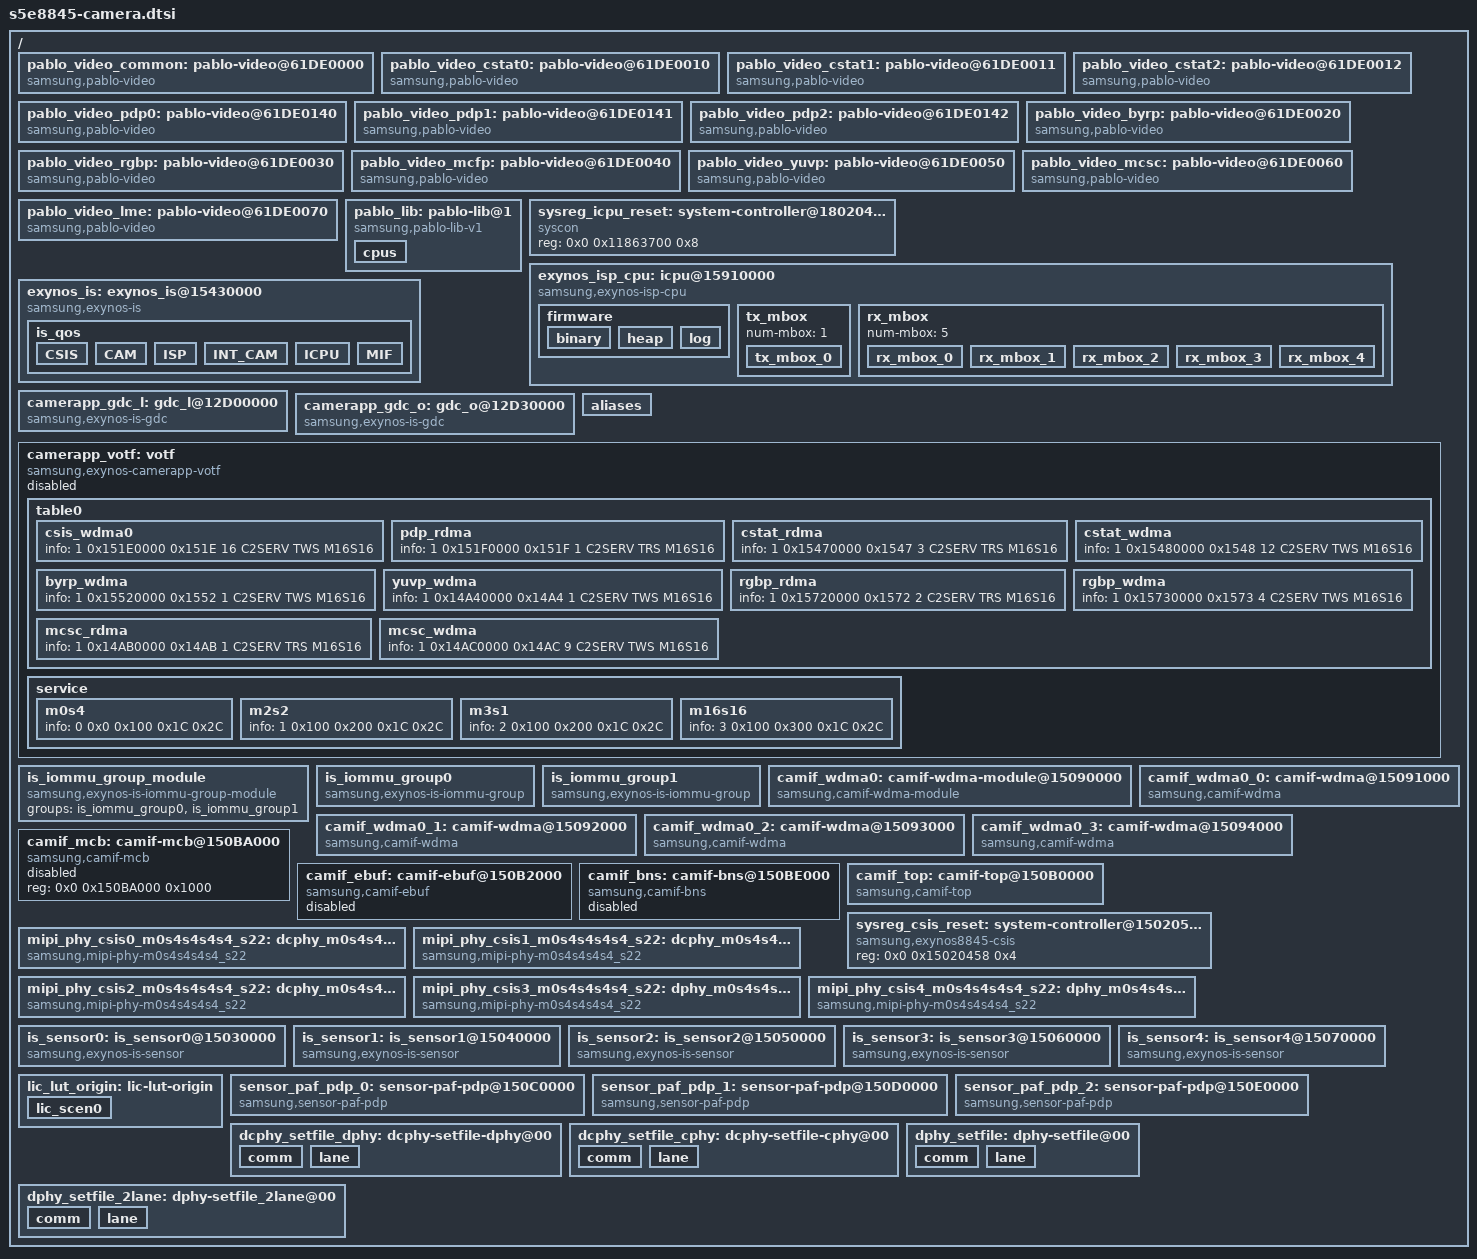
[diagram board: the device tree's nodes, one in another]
/*
 * SAMSUNG EXYNOS8845 SoC camera device tree source
 *
 * Copyright (c) 2023 Samsung Electronics Co., Ltd.
 *		http://www.samsung.com
 *
 * SAMSUNG EXYNOS8845 SoC camera device nodes are listed in this file.
 * EXYNOS8845 based board files can include this file and provide
 * values for board specfic bindings.
 *
 * This program is free software; you can redistribute it and/or modify
 * it under the terms of the GNU General Public License version 2 as
 * published by the Free Software Foundation.
 */

#include <dt-bindings/clock/s5e8845.h>
#include <dt-bindings/interrupt-controller/arm-gic.h>
#include <dt-bindings/interrupt-controller/s5e8845.h>
#include <dt-bindings/camera/exynos_is_dt.h>
#include <dt-bindings/camera/votf.h>
#include "s5e8845-pinctrl.dtsi"

/ {
	pablo_video_common: pablo-video@61DE0000 {
		compatible = "samsung,pablo-video";
		device-type = <1>;	/* ISCHAIN */
		video-type = <0>;	/* LEADER */
		video-name = "COMMON";
		video-number = <0>;
		group-id = <24>;
		group-slot = <0>;

		pablo,v4l2-dev = <&exynos_is>;
	};

	pablo_video_cstat0: pablo-video@61DE0010 {
		compatible = "samsung,pablo-video";
		device-type = <1>;      /* ISCHAIN */
		video-type = <0>;       /* LEADER */
		video-name = "CSTAT0";
		video-number = <10>;
		group-id = <0>;
		group-slot = <2>;

		pablo,v4l2-dev = <&exynos_is>;
	};

	pablo_video_cstat1: pablo-video@61DE0011 {
		compatible = "samsung,pablo-video";
		device-type = <1>;      /* ISCHAIN */
		video-type = <0>;       /* LEADER */
		video-name = "CSTAT1";
		video-number = <11>;
		group-id = <1>;
		group-slot = <2>;

		pablo,v4l2-dev = <&exynos_is>;
	};

	pablo_video_cstat2: pablo-video@61DE0012 {
		compatible = "samsung,pablo-video";
		device-type = <1>;      /* ISCHAIN */
		video-type = <0>;       /* LEADER */
		video-name = "CSTAT2";
		video-number = <12>;
		group-id = <2>;
		group-slot = <2>;

		pablo,v4l2-dev = <&exynos_is>;
	};

	pablo_video_pdp0: pablo-video@61DE0140 {
		compatible = "samsung,pablo-video";
		device-type = <1>;      /* ISCHAIN */
		video-type = <0>;       /* LEADER */
		video-name = "PDP0";
		video-number = <140>;
		group-id = <7>;
		group-slot = <1>;

		pablo,v4l2-dev = <&exynos_is>;
	};

	pablo_video_pdp1: pablo-video@61DE0141 {
		compatible = "samsung,pablo-video";
		device-type = <1>;      /* ISCHAIN */
		video-type = <0>;       /* LEADER */
		video-name = "PDP1";
		video-number = <141>;
		group-id = <8>;
		group-slot = <1>;

		pablo,v4l2-dev = <&exynos_is>;
	};

	pablo_video_pdp2: pablo-video@61DE0142 {
		compatible = "samsung,pablo-video";
		device-type = <1>;      /* ISCHAIN */
		video-type = <0>;       /* LEADER */
		video-name = "PDP2";
		video-number = <142>;
		group-id = <9>;
		group-slot = <1>;

		pablo,v4l2-dev = <&exynos_is>;
	};

	pablo_video_byrp: pablo-video@61DE0020 {
		compatible = "samsung,pablo-video";
		device-type = <1>;      /* ISCHAIN */
		video-type = <0>;       /* LEADER */
		video-name = "BYRP";
		video-number = <20>;
		group-id = <4>;
		group-slot = <4>;

		pablo,v4l2-dev = <&exynos_is>;
	};

	pablo_video_rgbp: pablo-video@61DE0030 {
		compatible = "samsung,pablo-video";
		device-type = <1>;      /* ISCHAIN */
		video-type = <0>;       /* LEADER */
		video-name = "RGBP";
		video-number = <30>;
		group-id = <5>;
		group-slot = <5>;

		pablo,v4l2-dev = <&exynos_is>;
	};

	pablo_video_mcfp: pablo-video@61DE0040 {
		compatible = "samsung,pablo-video";
		device-type = <1>;      /* ISCHAIN */
		video-type = <0>;       /* LEADER */
		video-name = "MCFP";
		video-number = <40>;
		group-id = <11>;
		group-slot = <6>;

		pablo,v4l2-dev = <&exynos_is>;
	};

	pablo_video_yuvp: pablo-video@61DE0050 {
		compatible = "samsung,pablo-video";
		device-type = <1>;      /* ISCHAIN */
		video-type = <0>;       /* LEADER */
		video-name = "YUVP";
		video-number = <50>;
		group-id = <12>;
		group-slot = <7>;

		pablo,v4l2-dev = <&exynos_is>;
	};

	pablo_video_mcsc: pablo-video@61DE0060 {
		compatible = "samsung,pablo-video";
		device-type = <1>;      /* ISCHAIN */
		video-type = <0>;       /* LEADER */
		video-name = "MCSC";
		video-number = <60>;
		group-id = <6>;
		group-slot = <8>;

		pablo,v4l2-dev = <&exynos_is>;
	};

	pablo_video_lme: pablo-video@61DE0070 {
		compatible = "samsung,pablo-video";
		device-type = <1>;      /* ISCHAIN */
		video-type = <0>;       /* LEADER */
		video-name = "LME";
		video-number = <70>;
		group-id = <13>;
		group-slot = <3>;

		pablo,v4l2-dev = <&exynos_is>;
	};

	pablo_lib: pablo-lib@1 {
		compatible = "samsung,pablo-lib-v1";
		status = "okay";

		cpus { /* 4:3:1 */
			cluster0 = <0>; /* LIT */
			cluster1 = <4>; /* MID */
			cluster2 = <7>; /* BIG */
		};
	};

	sysreg_icpu_reset: system-controller@1802040c {
		compatible = "syscon";
		reg = <0x0 0x11863700 0x8>;
	};

	exynos_isp_cpu: icpu@15910000 {
		compatible = "samsung,exynos-isp-cpu";
		reg = <0x0 0x15900000 0x50>,
			<0x0 0x15910000 0x1000>,
			<0x0 0x15970000 0x2000>,
			<0x0 0x15980000 0x100>;
		reg-names = "mcuctl_core", "mcuctl", "sysctrl", "cstore";
		interrupts = <0 INTREQ__FROM_ICPU_TO_HOST_3 IRQ_TYPE_LEVEL_HIGH>, /* mbox0 */
				<0 INTREQ__FROM_ICPU_TO_HOST_4 IRQ_TYPE_LEVEL_HIGH>, /* mbox1 */
				<0 INTREQ__FROM_ICPU_TO_HOST_5 IRQ_TYPE_LEVEL_HIGH>, /* mbox2 */
				<0 INTREQ__FROM_ICPU_TO_HOST_6 IRQ_TYPE_LEVEL_HIGH>, /* mbox3 */
				<0 INTREQ__FROM_ICPU_TO_HOST_7 IRQ_TYPE_LEVEL_HIGH>; /* mbox4 */
		clocks = <&clock GATE_ICPU_QCH_CPU0>;
		clock-names = "GATE_ICPU_QCH_CPU0";
		status = "okay";
		iommus = <&sysmmu_icpu_s0>;
		samsung,iommu-group = <&iommu_group_icpu>;
		samsung,reset-sysreg = <&sysreg_icpu_reset>;
		reset = <0>; /* reset bit */
		#dma-address-cells = <1>;
		#dma-size-cells = <1>;
		samsung,iommu-reserved-map =
			<0x0 0x10000000 0x1000000>, /* FW binary */
			<0x0 0x00000000 0x10000000>, /* ICPU MMU */
			<0x0 0x15900000 0x200000>; /* ICPU SFR */
		memory-region = <&icpu_fw_rmem>;

		force-powerdown-seq =
			/* type addr mask val timeout */
			<0 0x15970024 0xFFFFFFFF 0x1      0>, /* Enable CA32 Transaction block */
			<0 0x15980030 0xFFFFFFFF 0x3      0>, /* DMA Flush */
			<1 0x15970028 0xFFFFFFFF 0x0   1000>, /* Wait until # of CA32  transaction is 0 */
			<1 0x15980034 0x24       0x24  1000>, /* Wait DMA  flush is done */

			<0 0x15970004 0xFFFFFFFF 0x3F     0>, /* Q-channel disable(Always-on) */
			<0 0x15970030 0xFFFFFFFF 0x0      0>, /* Reset : Timers, WDT, GIC400, SYSCTRL */
			<0 0x1597002C 0xFFFFFFFF 0x0      0>, /* Reset : CA53, C_STORE */

			/* Need to PMU core reset */

			<0 0x15970004 0xFFFFFFFF 0x0      0>, /* Q-channel enable */
			<0 0x15803004 0xFFFFFFFF 0x4      0>, /* Q-ch & Clock Disable for ICPU_QCH_CPU0 */
			<0 0x1580300C 0xFFFFFFFF 0x4      0>, /* Q-ch & Clock Disable for ICPU_QCH_L2 */
			<0 0x15803010 0xFFFFFFFF 0x4      0>; /* Q-ch & Clock Disable for ICPU_QCH_NEON */

		samsung,imgloader-s2mpu-support;
		aarch64;
		firmware{
			binary{
				mem-id = <0>;
				cma-alloc;
				size = <0x1000000>;
				align = <0x200000>; /* 64K for S2MPU & ICPU MMU 2M page */
				signature-size = <0x210>; /* dec. 528 byte */
				signature-check;
				no-optimization;
			};

			heap{
				mem-id = <1>;
				dma-heap;
				heap-name = "system-uncached";
				size = <0x9600000>;
			};

			log{
				mem-id = <2>;
				dma-heap;
				heap-name = "system-uncached";
				size = <0x100000>;
			};
		};

		tx_mbox{
			num-mbox = <1>;
			tx_mbox_0{
				int-enable-offset = <0x1004>;
				int-gen-offset = <0x1400>;
				int-status-offset = <0x100c>;
				max-data-len = <16>;
				data-offset = <0x1440>;
			};
		};

		rx_mbox{
			num-mbox = <5>;
			rx_mbox_0{
				int-gen-offset = <0x1200>;
				int-status-offset = <0x1008>;
				max-data-len = <8>;
				data-offset = <0x1240>;
			};
			rx_mbox_1{
				int-gen-offset = <0x1204>;
				int-status-offset = <0x1008>;
				max-data-len = <8>;
				data-offset = <0x1260>;
			};
			rx_mbox_2{
				int-gen-offset = <0x1208>;
				int-status-offset = <0x1008>;
				max-data-len = <8>;
				data-offset = <0x1280>;
			};
			rx_mbox_3{
				int-gen-offset = <0x120c>;
				int-status-offset = <0x1008>;
				max-data-len = <8>;
				data-offset = <0x12a0>;
			};
			rx_mbox_4{
				int-gen-offset = <0x1210>;
				int-status-offset = <0x1008>;
				max-data-len = <8>;
				data-offset = <0x12c0>;
			};
		};
	};

	exynos_is: exynos_is@15430000 {
		compatible = "samsung,exynos-is";
		reg = <0x0 0x15430000 0x10000>, /* CSTAT0 */
			<0x0 0x15440000 0x10000>, /* CSTAT1 */
			<0x0 0x15450000 0x10000>, /* CSTAT2 */
			<0x0 0x12C80000 0x10000>, /* LME */
			<0x0 0x15500000 0x10000>, /* BYRP */
			<0x0 0x15700000 0x10000>, /* RGBP */
			<0x0 0x15780000 0x10000>, /* MCFP */
			<0x0 0x14A30000 0x10000>, /* YUVP */
			<0x0 0x14AA0000 0x10000>; /* MCSC */
		interrupts = <0 INTREQ__CSTAT_CH0_0 IRQ_TYPE_LEVEL_HIGH>, /*CSTAT0_0 */
			<0 INTREQ__CSTAT_CH0_1 IRQ_TYPE_LEVEL_HIGH>,      /* CSTAT0_1 */
			<0 INTREQ__CSTAT_CH1_0 IRQ_TYPE_LEVEL_HIGH>,      /* CSTAT1_0 */
			<0 INTREQ__CSTAT_CH1_1 IRQ_TYPE_LEVEL_HIGH>,      /* CSTAT1_1 */
			<0 INTREQ__CSTAT_CH2_0 IRQ_TYPE_LEVEL_HIGH>,      /* CSTAT2_0 */
			<0 INTREQ__CSTAT_CH2_1 IRQ_TYPE_LEVEL_HIGH>,      /* CSTAT2_1 */
			<0 INTREQ__LME_O_INT_0 IRQ_TYPE_LEVEL_HIGH>,       /* LME_0 */
			<0 INTREQ__BYRP_0 IRQ_TYPE_LEVEL_HIGH>,           /* BYRP_0 */
			<0 INTREQ__BYRP_1 IRQ_TYPE_LEVEL_HIGH>,           /* BYRP_1 */
			<0 INTREQ__RGBP_0 IRQ_TYPE_LEVEL_HIGH>,           /* RGBP_0 */
			<0 INTREQ__RGBP_1 IRQ_TYPE_LEVEL_HIGH>,           /* RGBP_1 */
			<0 INTREQ__MCFP_0 IRQ_TYPE_LEVEL_HIGH>,	/* MCFP_0 */
			<0 INTREQ__MCFP_1 IRQ_TYPE_LEVEL_HIGH>,	/* MCFP_1 */
			<0 INTREQ__YUVP_0 IRQ_TYPE_LEVEL_HIGH>,           /* YUVP_0 */
			<0 INTREQ__YUVP_1 IRQ_TYPE_LEVEL_HIGH>,           /* YUVP_1 */
			<0 INTREQ__MCSC_0 IRQ_TYPE_LEVEL_HIGH>,    /* MCSC_0 */
			<0 INTREQ__MCSC_1 IRQ_TYPE_LEVEL_HIGH>;    /* MCSC_1 */
		pinctrl-names = "default","release";
		pinctrl-0 = <>;
		pinctrl-1 = <>;
		clocks = <&clock GATE_DFTMUX_CMU_QCH_CIS_CLK0>,
		      <&clock GATE_DFTMUX_CMU_QCH_CIS_CLK1>,
		      <&clock GATE_DFTMUX_CMU_QCH_CIS_CLK2>,
		      <&clock GATE_DFTMUX_CMU_QCH_CIS_CLK3>,
		      <&clock GATE_DFTMUX_CMU_QCH_CIS_CLK4>,

		      <&clock DOUT_DIV_CLKCMU_CIS_CLK0>,
		      <&clock DOUT_DIV_CLKCMU_CIS_CLK1>,
		      <&clock DOUT_DIV_CLKCMU_CIS_CLK2>,
		      <&clock DOUT_DIV_CLKCMU_CIS_CLK3>,
		      <&clock DOUT_DIV_CLKCMU_CIS_CLK4>,

		      <&clock GATE_CSIS_PDP_QCH_DMA>,

		      <&clock GATE_MIPI_PHY_LINK_WRAP_QCH_CSIS0>,
		      <&clock GATE_MIPI_PHY_LINK_WRAP_QCH_CSIS1>,
		      <&clock GATE_MIPI_PHY_LINK_WRAP_QCH_CSIS2>,
		      <&clock GATE_MIPI_PHY_LINK_WRAP_QCH_CSIS3>,
		      <&clock GATE_MIPI_PHY_LINK_WRAP_QCH_CSIS4>,

		      <&clock GATE_CSIS_PDP_QCH_PDP>,
		      <&clock GATE_LH_AST_SI_OTF0_CSISCSTAT_QCH>,
		      <&clock GATE_LH_AST_SI_OTF1_CSISCSTAT_QCH>,
		      <&clock GATE_LH_AST_SI_OTF2_CSISCSTAT_QCH>,
		      <&clock GATE_M2M_QCH_S1>,
		      <&clock GATE_MCFP_QCH>,
		      <&clock GATE_YUVP_QCH>,
		      <&clock GATE_MCSC_QCH>;
		clock-names = "GATE_DFTMUX_CMU_QCH_CIS_CLK0",
			"GATE_DFTMUX_CMU_QCH_CIS_CLK1",
			"GATE_DFTMUX_CMU_QCH_CIS_CLK2",
			"GATE_DFTMUX_CMU_QCH_CIS_CLK3",
			"GATE_DFTMUX_CMU_QCH_CIS_CLK4",

			"DOUT_DIV_CLKCMU_CIS_CLK0",
			"DOUT_DIV_CLKCMU_CIS_CLK1",
			"DOUT_DIV_CLKCMU_CIS_CLK2",
			"DOUT_DIV_CLKCMU_CIS_CLK3",
			"DOUT_DIV_CLKCMU_CIS_CLK4",

			"GATE_CSIS_PDP_QCH_DMA",

			"GATE_MIPI_PHY_LINK_WRAP_QCH_CSIS0",
			"GATE_MIPI_PHY_LINK_WRAP_QCH_CSIS1",
			"GATE_MIPI_PHY_LINK_WRAP_QCH_CSIS2",
			"GATE_MIPI_PHY_LINK_WRAP_QCH_CSIS3",
			"GATE_MIPI_PHY_LINK_WRAP_QCH_CSIS4",

			"GATE_CSIS_PDP_QCH_PDP",
			"GATE_LH_AST_SI_OTF0_CSISCSTAT_QCH",
			"GATE_LH_AST_SI_OTF1_CSISCSTAT_QCH",
			"GATE_LH_AST_SI_OTF2_CSISCSTAT_QCH",
			"GATE_M2M_QCH_S1",
			"GATE_MCFP_QCH",
			"GATE_YUVP_QCH",
			"GATE_MCSC_QCH";
		status = "ok";
		iommus = <&sysmmu_csis_s0>,
			<&sysmmu_cstat_s0>,
			<&sysmmu_yuvp_s0>,
			<&sysmmu_rgbp_s0>;
		samsung,iommu-group = <&iommu_group_is>;
		#cooling-cells = <2>; /* min followed by max */
		/* ewf-index = <EWF_CMU_BUSC>; */
		list-scen-bts = "camera_default", "camera_heavy";
		itmon_port_name = "CSIS", "LME", "CSTAT", "YUVP", "MCSC", "MCFP", "RGBP", "BYRP", "ICPU";
		num_of_3aa = <3>;
		num_of_lme = <1>;
		num_of_isp = <0>;
		num_of_byrp = <1>;
		num_of_rgbp = <1>;
		num_of_mcsc = <1>;
		num_of_vra = <0>;
		num_of_clh = <0>;
		num_of_ypp = <1>;
		num_of_shrp = <0>;
		num_of_mcfp = <1>;
		num_of_dlfe = <0>;

		samsung,tzmp;

		phy_ldos = "vdd_ldo3", "vdd_ldo13";

		is_qos {
			CSIS { /* CSIS, PDP, CSTAT */
				typ = <IS_DVFS_CSIS>;
				lev = <0      1      2      3      4      5      6      /* 7 */>;
				frq = <666    533    444    400    333    267    200    /* 89 */>;
				qos = <666000 533000 444000 400000 333000 267000 200000 /* 89000 */>;
				otf;
			};

			CAM { /* BYRP, RGBP, MCSC, ICPU */
				typ = <IS_DVFS_CAM>;
				lev = <0      1      2      3      4      5      6      /* 7 */>;
				frq = <666    533    444    400    333    267    200    /* 89 */>;
				qos = <666000 533000 444000 400000 333000 267000 200000 /* 89000 */>;
			};

			ISP { /* MCFP, YUVP */
				typ = <IS_DVFS_ISP>;
				lev = <0      1      2      3      4      5      6      /* 7 */>;
				frq = <666    533    444    400    333    267    200    /* 89 */>;
				qos = <666000 533000 444000 400000 333000 267000 200000 /* 89000 */>;
			};

			INT_CAM { /* LME, GDC */
				typ = <IS_DVFS_INT_CAM>;
				lev = <0      1      2      3      4      5      6      /* 7 */>;
				frq = <666    533    444    333    267    200    134    /* 89 */>;
				qos = <800000 533000 444000 333000 267000 200000 134000 /* 89000 */>;
			};

			ICPU { /* ICPU */
				typ = <IS_DVFS_ICPU>;
				lev = <0       1       2       3      4      5      6      /* 7 */>;
				frq = <1200    800    600    444    400    300    267    /* 89 */>;
				qos = <1200000 800000 600000 444000 400000 300000 267000 /* 89000 */>;
			};

			MIF {
				typ = <IS_DVFS_MIF>;
				lev = <0       1       2       3       4       5       6       7       8       9      10     11     12>;
				frq = <3172    2730    2535    2288    2093    1794    1539    1352    1014    845    676    546    421>;
				qos = <3172000 2730000 2535000 2288000 2093000 1794000 1539000 1352000 1014000 845000 676000 546000 421000>;
			};
		};
	};

	camerapp_gdc_l: gdc_l@12D00000 {
		compatible = "samsung,exynos-is-gdc";
		reg = <0x0 0x12D00000 0x10000>; /* GDC */
		interrupts = <0 INTREQ__GDC_L_IRQ_0 IRQ_TYPE_LEVEL_HIGH>, /* GDC_0 */
			<0 INTREQ__GDC_L_IRQ_1 IRQ_TYPE_LEVEL_HIGH>;    /* GDC_1 */
		pinctrl-names = "default","release";
		pinctrl-0 = <>;
		pinctrl-1 = <>;
		clocks = <&clock GATE_M2M_QCH_S1>;
		clock-names = "gate";

		status = "okay";
		iommus = <&sysmmu_m2m_s0>;
		samsung,iommu-group = <&iommu_group_mscl_smfc>;
		#cooling-cells = <2>; /* min followed by max */
	};

	camerapp_gdc_o: gdc_o@12D30000 {
		compatible = "samsung,exynos-is-gdc";
		reg = <0x0 0x12D30000 0x10000>; /* GDC */
		interrupts = <0 INTREQ__GDC_O_IRQ_0 IRQ_TYPE_LEVEL_HIGH>, /* GDC_0 */
			<0 INTREQ__GDC_O_IRQ_1 IRQ_TYPE_LEVEL_HIGH>;    /* GDC_1 */
		pinctrl-names = "default","release";
		pinctrl-0 = <>;
		pinctrl-1 = <>;
		clocks = <&clock GATE_M2M_QCH_S2>;
		clock-names = "gate";

		status = "okay";
		iommus = <&sysmmu_m2m_s0>;
		samsung,iommu-group = <&iommu_group_mscl_smfc>;
		#cooling-cells = <2>; /* min followed by max */
	};

	aliases {
		pablo-gdc0 = &camerapp_gdc_o;
		pablo-gdc1 = &camerapp_gdc_l;
	};

	camerapp_votf: votf {
		compatible = "samsung,exynos-camerapp-votf";
		iommus = <&sysmmu_csis_s0>,
			<&sysmmu_cstat_s0>,
			<&sysmmu_yuvp_s0>,
			<&sysmmu_rgbp_s0>;
		samsung,iommu-group = <&iommu_group_is>;
		samsung,iommu-identity-map =    <0x0 0x151E0000 0x10000>,
						<0x0 0x151F0000 0x10000>,
						<0x0 0x15520000 0x10000>,
						<0x0 0x15470000 0x10000>,
						<0x0 0x15480000 0x10000>,
						<0x0 0x14A40000 0x10000>,
						<0x0 0x15720000 0x10000>,
						<0x0 0x15730000 0x10000>,
						<0x0 0x14AB0000 0x10000>,
						<0x0 0x14AC0000 0x10000>;
		status = "disabled";
		use_axi;

		table0{
			/* use, base address, ip num, id cnt, C2SERV/C2AGENT, TWS/TRS, module type */
			csis_wdma0	{ info = <1 0x151E0000 0x151E 16 C2SERV TWS M16S16>; };
			pdp_rdma	{ info = <1 0x151F0000 0x151F 1 C2SERV TRS M16S16>; };
			cstat_rdma	{ info = <1 0x15470000 0x1547 3 C2SERV TRS M16S16>; };
			cstat_wdma	{ info = <1 0x15480000 0x1548 12 C2SERV TWS M16S16>; };
			byrp_wdma	{ info = <1 0x15520000 0x1552 1 C2SERV TWS M16S16>; };
			yuvp_wdma	{ info = <1 0x14A40000 0x14A4 1 C2SERV TWS M16S16>; };
			rgbp_rdma	{ info = <1 0x15720000 0x1572 2 C2SERV TRS M16S16>; };
			rgbp_wdma	{ info = <1 0x15730000 0x1573 4 C2SERV TWS M16S16>; };
			mcsc_rdma	{ info = <1 0x14AB0000 0x14AB 1 C2SERV TRS M16S16>; };
			mcsc_wdma	{ info = <1 0x14AC0000 0x14AC 9 C2SERV TWS M16S16>; };
		};

		service {
			/* num, tws addr, trs addr, tws gap, trs gap */
			m0s4 { info = <0 0x0 0x100 0x1C 0x2C>; };
			m2s2 { info = <1 0x100 0x200 0x1C 0x2C>; };
			m3s1 { info = <2 0x100 0x200 0x1C 0x2C>; };
			m16s16 { info = <3 0x100 0x300 0x1C 0x2C>; };
		};
	};

	is_iommu_group_module: is_iommu_group_module {
		compatible = "samsung,exynos-is-iommu-group-module";
		groups = <&is_iommu_group0>,
			<&is_iommu_group1>;
	};

	aliases {
		iommu-group-module0 = &is_iommu_group_module;
	};

	is_iommu_group0: is_iommu_group0 {
		compatible = "samsung,exynos-is-iommu-group";
		iommus = <&sysmmu_csis_s0>,
			<&sysmmu_cstat_s0>,
			<&sysmmu_yuvp_s0>,
			<&sysmmu_rgbp_s0>;
		samsung,iommu-group = <&iommu_group_is>;
	};

	is_iommu_group1: is_iommu_group1 {
		compatible = "samsung,exynos-is-iommu-group";
		iommus = <&sysmmu_m2m_s0>;
		samsung,iommu-group = <&iommu_group_mscl_smfc>;
	};

	aliases {
		iommu-group0 = &is_iommu_group0;
		iommu-group1 = &is_iommu_group1;
	};

	camif_wdma0: camif-wdma-module@15090000 {
		compatible = "samsung,camif-wdma-module";
		reg = <0x0 0x15090000 0x300>;
		reg-names = "ctl";
		channels = <&camif_wdma0_0>,
			<&camif_wdma0_1>,
			<&camif_wdma0_2>,
			<&camif_wdma0_3>;
		samsung,quirks = "has test pattern gen";
	};

	aliases {
		wdma-module0 = &camif_wdma0;
	};

	camif_wdma0_0: camif-wdma@15091000 {
		compatible = "samsung,camif-wdma";
		reg = <0x0 0x150B0240 0x4>,	/* input MUX */
			<0x0 0x15091400 0x100>,	/* CTL */
			<0x0 0x15091000 0x100>,	/* VC0 */
			<0x0 0x15091100 0x100>,	/* VC1 */
			<0x0 0x15091200 0x100>,	/* VC2 */
			<0x0 0x15091300 0x100>;	/* VC3 */
		reg-names = "mux", "ctl", "vc0", "vc1", "vc2", "vc3";
		interrupts = <GIC_SPI INTREQ__CSIS_DMA0 IRQ_TYPE_LEVEL_HIGH>;
		interrupt-names = "dma";
		module = <&camif_wdma0>;
		sysmmu_port = <0>;
	};

	camif_wdma0_1: camif-wdma@15092000 {
		compatible = "samsung,camif-wdma";
		reg = <0x0 0x150B0244 0x4>,	/* input MUX */
			<0x0 0x15092400 0x100>,	/* CTL */
			<0x0 0x15092000 0x100>,	/* VC0 */
			<0x0 0x15092100 0x100>,	/* VC1 */
			<0x0 0x15092200 0x100>,	/* VC2 */
			<0x0 0x15092300 0x100>;	/* VC3 */
		reg-names = "mux", "ctl", "vc0", "vc1", "vc2", "vc3";
		interrupts = <GIC_SPI INTREQ__CSIS_DMA1 IRQ_TYPE_LEVEL_HIGH>;
		interrupt-names = "dma";
		module = <&camif_wdma0>;
		sysmmu_port = <0>;
	};

	camif_wdma0_2: camif-wdma@15093000 {
		compatible = "samsung,camif-wdma";
		reg = <0x0 0x150B0248 0x4>,	/* input MUX */
			<0x0 0x15093400 0x100>,	/* CTL */
			<0x0 0x15093000 0x100>,	/* VC0 */
			<0x0 0x15093100 0x100>,	/* VC1 */
			<0x0 0x15093200 0x100>,	/* VC2 */
			<0x0 0x15093300 0x100>;	/* VC3 */
		reg-names = "mux", "ctl", "vc0", "vc1", "vc2", "vc3";
		interrupts = <GIC_SPI INTREQ__CSIS_DMA2 IRQ_TYPE_LEVEL_HIGH>;
		interrupt-names = "dma";
		module = <&camif_wdma0>;
		sysmmu_port = <1>;
	};

	camif_wdma0_3: camif-wdma@15094000 {
		compatible = "samsung,camif-wdma";
		reg = <0x0 0x150B024C 0x4>,	/* input MUX */
			<0x0 0x15094400 0x100>,	/* CTL */
			<0x0 0x15094000 0x100>,	/* VC0 */
			<0x0 0x15094100 0x100>,	/* VC1 */
			<0x0 0x15094200 0x100>,	/* VC2 */
			<0x0 0x15094300 0x100>;	/* VC3 */
		reg-names = "mux", "ctl", "vc0", "vc1", "vc2", "vc3";
		interrupts = <GIC_SPI INTREQ__CSIS_DMA3 IRQ_TYPE_LEVEL_HIGH>;
		interrupt-names = "dma";
		module = <&camif_wdma0>;
		sysmmu_port = <1>;
	};

	aliases {
		wdma0 = &camif_wdma0_0;
		wdma1 = &camif_wdma0_1;
		wdma2 = &camif_wdma0_2;
		wdma3 = &camif_wdma0_3;
	};

	camif_mcb: camif-mcb@150BA000 {
		compatible = "samsung,camif-mcb";
		reg = <0x0 0x150BA000 0x1000>;
		status = "disabled";
	};

	camif_ebuf: camif-ebuf@150B2000 {
		compatible = "samsung,camif-ebuf";
		reg = <0x0 0x150B2000 0x100>;
		interrupts = <0 INTREQ__SENSOR_ABORT IRQ_TYPE_LEVEL_HIGH>;
		num_of_ebuf = <3>;
		fake_done_offset = <4>;
		status = "disabled";
	};

	camif_bns: camif-bns@150BE000 {
		compatible = "samsung,camif-bns";
		reg = <0x0 0x150BE000 0x100>,
		    <0x0 0x150B020C 0x4>; /* CSIS_PDP_BNS_MUX */
		reg-names = "ctl", "mux";

		mux = <0 1 2 3>; /* BNS in/out channel selection */
		dma_mux = <0x24>; /* DMA mux for BNS out */
		status = "disabled";
	};

	camif_top: camif-top@150B0000 {
		compatible = "samsung,camif-top";
		reg = <0x0 0x150B0000 0x10000>;
		interrupts = <0 INTREQ__CSIS_TOP IRQ_TYPE_LEVEL_HIGH>;
	};

	sysreg_csis_reset: system-controller@15020500 {
		compatible = "samsung,exynos8845-csis", "syscon";
		reg = <0x0 0x15020458 0x4>;
	};

	mipi_phy_csis0_m0s4s4s4s4_s22: dcphy_m0s4s4s4s4_s22_csi0@150F1300 {
		/* DPHY 2.5 Gbps 4lane */
		/* CPHY 4.5 Gbps 3lane */
		compatible = "samsung,mipi-phy-m0s4s4s4s4_s22";
		samsung,pmu-syscon = <&pmu_system_controller>;
		power-gating = <0x648>; /* PMU address offset */
		samsung,reset-sysreg = <&sysreg_csis_reset>;
		reset = <0>; /* reset bit */
		reg = <0x0 0x150F1300 0x500>;
		owner = <1>; /* 0: DSI,  1: CSI */
		#phy-cells = <1>;
	};

	mipi_phy_csis1_m0s4s4s4s4_s22: dcphy_m0s4s4s4s4_s22_csi1@150F1B00 {
		/* DPHY 2.5 Gbps 4lane */
		/* CPHY 4.5 Gbps 3lane */
		compatible = "samsung,mipi-phy-m0s4s4s4s4_s22";
		samsung,pmu-syscon = <&pmu_system_controller>;
		power-gating = <0x64C>; /* PMU address offset */
		samsung,reset-sysreg = <&sysreg_csis_reset>;
		reset = <1>; /* reset bit */
		reg = <0x0 0x150F1B00 0x500>;
		owner = <1>; /* 0: DSI,  1: CSI */
		#phy-cells = <1>;
	};

	mipi_phy_csis2_m0s4s4s4s4_s22: dcphy_m0s4s4s4s4_s22_csi2@150F2300 {
		/* DPHY 2.5 Gbps 4lane */
		/* CPHY 4.5 Gbps 3lane */
		compatible = "samsung,mipi-phy-m0s4s4s4s4_s22";
		samsung,pmu-syscon = <&pmu_system_controller>;
		power-gating = <0x650>; /* PMU address offset */
		samsung,reset-sysreg = <&sysreg_csis_reset>;
		reset = <2>; /* reset bit */
		reg = <0x0 0x150F2300 0x500>;
		owner = <1>; /* 0: DSI,  1: CSI */
		#phy-cells = <1>;
	};

	mipi_phy_csis3_m0s4s4s4s4_s22: dphy_m0s4s4s4s4_s22_csi3@150F2B00 {
		/* DPHY 2.5 Gbps 4lane */
		compatible = "samsung,mipi-phy-m0s4s4s4s4_s22";
		samsung,pmu-syscon = <&pmu_system_controller>;
		power-gating = <0x654>, <0x658>; /* PMU address offset */
		samsung,reset-sysreg = <&sysreg_csis_reset>;
		reset = <3>; /* reset bit */
		reg = <0x0 0x150F2B00 0x500>;
		owner = <1>; /* 0: DSI,  1: CSI */
		#phy-cells = <1>;
	};

	mipi_phy_csis4_m0s4s4s4s4_s22: dphy_m0s4s4s4s4_s22_csi4@150F2A00 {
		/* DPHY 2.5 Gbps 2lane */
		compatible = "samsung,mipi-phy-m0s4s4s4s4_s22";
		samsung,pmu-syscon = <&pmu_system_controller>;
		power-gating = <0x658>; /* PMU address offset */
		samsung,reset-sysreg = <&sysreg_csis_reset>;
		reset = <4>; /* reset bit */
		reg = <0x0 0x150F2A00 0x100>,	/* clock */
			<0x0 0x150F2E00 0x200>; /* lane */
		owner = <1>; /* 0: DSI,  1: CSI */
		#phy-cells = <1>;
	};

	is_sensor0: is_sensor0@15030000 {
		/* CSIS0 */
		compatible = "samsung,exynos-is-sensor";
		reg = <0x0 0x15030000 0x1000>, /* MIPI-CSI0 */
			<0x0 0x150F0000 0x10000>, /* PHY: M0S4S4S4_S22 */
			<0x0 0x150B022C 0x10>, /* CSIS_FRO */
			<0x0 0x150B0254 0x10>; /* CSIS 5x3 OTF_OUT MUX  ==> no use : need to remove */
		reg-names = "csi", "phy", "fro", "otf_out_mux";
		interrupts = <0 INTREQ__CSIS0 IRQ_TYPE_LEVEL_HIGH>; /*MIPI-CSI0 */
		interrupt-names = "csi";
		phys = <&mipi_phy_csis0_m0s4s4s4s4_s22 0>;
		phy-names = "csis_dphy";
		phy_setfile = <&dcphy_setfile_cphy>;
		iommus = <&sysmmu_csis_s0>;
		samsung,iommu-group = <&iommu_group_is>;
	};

	is_sensor1: is_sensor1@15040000 {
		/* CSIS1 */
		compatible = "samsung,exynos-is-sensor";
		reg = <0x0 0x15040000 0x1000>, /* MIPI-CSI1 */
			<0x0 0x150F0000 0x10000>, /* PHY: M0S4S4S4_S22 */
			<0x0 0x150B022C 0x10>, /* CSIS_FRO */
			<0x0 0x150B0254 0x10>; /* CSIS 5x3 OTF_OUT MUX */
		reg-names = "csi", "phy", "fro", "otf_out_mux";
		interrupts = <0 INTREQ__CSIS1 IRQ_TYPE_LEVEL_HIGH>; /* MIPI-CSI1 */
		interrupt-names = "csi";
		phys = <&mipi_phy_csis1_m0s4s4s4s4_s22 0>;
		phy-names = "csis_dphy";
		phy_setfile = <&dcphy_setfile_cphy>;
		iommus = <&sysmmu_csis_s0>;
		samsung,iommu-group = <&iommu_group_is>;
		/* samsung,tzmp; */
	};

	is_sensor2: is_sensor2@15050000 {
		/* CSIS2 */
		compatible = "samsung,exynos-is-sensor";
		reg = <0x0 0x15050000 0x1000>, /* MIPI-CSI2 */
			<0x0 0x150F0000 0x10000>, /* PHY: M0S4S4S4S4S4S2 */
			<0x0 0x150B022C 0x10>, /* CSIS_FRO */
			<0x0 0x150B0254 0x10>; /* CSIS 5x3 OTF_OUT MUX */
		reg-names = "csi", "phy", "fro", "otf_out_mux";
		interrupts = <0 INTREQ__CSIS2 IRQ_TYPE_LEVEL_HIGH>; /* MIPI-CSI2 */
		interrupt-names = "csi";
		phys = <&mipi_phy_csis2_m0s4s4s4s4_s22 0>;
		phy-names = "csis_dphy";
		phy_setfile = <&dcphy_setfile_dphy>;
		iommus = <&sysmmu_csis_s0>;
		samsung,iommu-group = <&iommu_group_is>;
	};

	is_sensor3: is_sensor3@15060000 {
		/* CSIS3 */
		compatible = "samsung,exynos-is-sensor";
		reg = <0x0 0x15060000 0x1000>, /* MIPI-CSI3 */
			<0x0 0x150F0000 0x10000>, /* PHY: M0S4S4S4S4S4S2 */
			<0x0 0x150B022C 0x10>, /* CSIS_FRO */
			<0x0 0x150B0254 0x10>; /* CSIS 5x3 OTF_OUT MUX */
		reg-names = "csi", "phy", "fro", "otf_out_mux";
		interrupts = <0 INTREQ__CSIS3 IRQ_TYPE_LEVEL_HIGH>; /* MIPI-CSI3 */
		interrupt-names = "csi";
		phys = <&mipi_phy_csis3_m0s4s4s4s4_s22 0>;
		phy-names = "csis_dphy";
		phy_setfile = <&dphy_setfile>;
		iommus = <&sysmmu_csis_s0>;
		samsung,iommu-group = <&iommu_group_is>;
	};

	is_sensor4: is_sensor4@15070000 {
		/* CSIS4 */
		compatible = "samsung,exynos-is-sensor";
		reg = <0x0 0x15070000 0x1000>, /* MIPI-CSI4 */
			<0x0 0x150F0000 0x10000>, /* PHY: M0S4S4S4S4S4S2 */
			<0x0 0x150B022C 0x10>, /* CSIS_FRO */
			<0x0 0x150B0254 0x10>; /* CSIS 5x3 OTF_OUT MUX */
		reg-names = "csi", "phy", "fro", "otf_out_mux";
		interrupts = <0 INTREQ__CSIS4 IRQ_TYPE_LEVEL_HIGH>; /* MIPI-CSI4 */
		interrupt-names = "csi";
		phys = <&mipi_phy_csis4_m0s4s4s4s4_s22 0>;
		phy-names = "csis_dphy";
		phy_setfile = <&dphy_setfile_2lane>;
		iommus = <&sysmmu_csis_s0>;
		samsung,iommu-group = <&iommu_group_is>;
	};

	lic_lut_origin: lic-lut-origin {
		#define LIC_MODE_DYNAMIC	(0)
		#define LIC_MODE_STATIC		(1)
		#define LIC_PATH_OTF		(0)
		#define LIC_PATH_DMA		(1)

		lic_mode_default = <LIC_MODE_DYNAMIC>;
		lic_14bit = <0>;
		lic_dma_only = <0>; /* Use this when NOT using OTF input at all. */

		/*
		 * When DYNAMIC mode is selected, param means enable limitation for DMA path.
		 * Example:
		 * @ mode = <LIC_MODE_DYNAMIC>;
		 * @ param0 = <LIC_PATH_OTF>;
		 * @ param1 = <LIC_PATH_DMA>;
		 * @ param2 = <LIC_PATH_OTF>;
		 *
		 * When STATIC mode is selected, param means buffer size for each context.
		 * Example:
		 * @ mode = <LIC_MODE_STAIC>;
		 * @ param0 = <3584>;
		 * @ param1 = <3583>;
		 * @ param2 = <1>;
		 *
		 * The lic_scen0 is not abailable. If the index of LUT is "0", the selection is skipped.
		 */
		lic_scen0 { /* Reserved */
			mode = <0>;
			param0 = <0>;
			param1 = <0>;
			param2 = <0>;
		};
	};

	sensor_paf_pdp_0: sensor-paf-pdp@150C0000 {
		compatible = "samsung,sensor-paf-pdp";
		reg = <0x0 0x150C0000 0x10000>, /* PDP CORE0 */
			<0x0 0x150C0000 0x10000>; /* PDP CORE0: For common regiser */
		reg-names = "core", "common";
		interrupts = <0 INTREQ__PDP0 IRQ_TYPE_LEVEL_HIGH>,
			<0 INTREQ__PDP1 IRQ_TYPE_LEVEL_HIGH>;
		leader; /* have RDMA & create video node */
		lic_lut = <&lic_lut_origin>;
	};

	sensor_paf_pdp_1: sensor-paf-pdp@150D0000 {
		compatible = "samsung,sensor-paf-pdp";
		reg = <0x0 0x150D0000 0x10000>, /* PDP CORE1 */
			<0x0 0x150C0000 0x10000>; /* PDP CORE0: For common regiser */
		reg-names = "core", "common";
		interrupts = <0 INTREQ__PDP2 IRQ_TYPE_LEVEL_HIGH>,
			<0 INTREQ__PDP3 IRQ_TYPE_LEVEL_HIGH>;
		leader; /* have RDMA & create video node */
		lic_lut = <&lic_lut_origin>;
	};

	sensor_paf_pdp_2: sensor-paf-pdp@150E0000 {
		compatible = "samsung,sensor-paf-pdp";
		reg = <0x0 0x150E0000 0x10000>, /* PDP CORE2 */
			<0x0 0x150C0000 0x10000>; /* PDP CORE0: For common regiser */
		reg-names = "core", "common";
		interrupts = <0 INTREQ__PDP4 IRQ_TYPE_LEVEL_HIGH>,
			<0 INTREQ__PDP5 IRQ_TYPE_LEVEL_HIGH>;
		leader; /* have RDMA & create video node */
		lic_lut = <&lic_lut_origin>;
	};

	aliases {
		pdp0 = &sensor_paf_pdp_0;
		pdp1 = &sensor_paf_pdp_1;
		pdp2 = &sensor_paf_pdp_2;
	};

	/*
	 * default setfiles for DPHY & CPHY
	 * <addr, bit_start, bit_width, val, index, max_lane>
	 */
	dcphy_setfile_dphy: dcphy-setfile-dphy@00 {
		comm {
			/* bias */
			0  = <0x1000 0 32 0x00000010 IDX_BIA_VAL 0>; /* M_BIAS_CON0 */
			1  = <0x1004 0 32 0x00000110 IDX_BIA_VAL 0>; /* M_BIAS_CON1 */
			2  = <0x1008 0 32 0x00003223 IDX_BIA_VAL 0>; /* M_BIAS_CON2 */
			3  = <0x1010 0 32 0x00000200 IDX_BIA_VAL 0>; /* M_BIAS_CON4 */

			/* clock */
			4 = <0x0004 0 32 0x00003C00 IDX_FIX_VAL 0>; /* SC_GNR_CON1 */
			5 = <0x0008 0 32 0x00000001 IDX_FIX_VAL 0>; /* SC_ANA_CON0 */
			6 = <0x000C 0 32 0x0000F4AE IDX_FIX_VAL 0>; /* SC_ANA_CON1 */
			7 = <0x0010 0 32 0x00000002 IDX_FIX_VAL 0>; /* SC_ANA_CON2 */
			8 = <0x0014 0 32 0x00008600 IDX_FIX_VAL 0>; /* SC_ANA_CON3 */
			9 = <0x0018 0 32 0x00004000 IDX_FIX_VAL 0>; /* SC_ANA_CON4 */
			10 = <0x0030 0 32 0x00000409 IDX_FIX_VAL 0>; /* SC_TIME_CON0 */
			/* Enable should be set at last. */
			11 = <0x0000 0 32 0x00000001 IDX_FIX_VAL 0>; /* SC_GNR_CON0, Phy clock enable */
		};

		lane {
			0  = <0x0004 0 32 0x00003C00 IDX_FIX_VAL 4>; /* SD_GNR_CON1 */
			1  = <0x0008 0 32 0x00000001 IDX_FIX_VAL 4>; /* SD_ANA_CON0 */
			2  = <0x000C 0 32 0x0000F4AE IDX_FIX_VAL 4>; /* SD_ANA_CON1 */
			3  = <0x0010 0 32 0x00000002 IDX_FIX_VAL 4>; /* SD_ANA_CON2 */
			4  = <0x0010 8  2 0x00000000 IDX_SKW_DLY 4>; /* SD_ANA_CON2 */
			5  = <0x0014 0 32 0x00008600 IDX_FIX_VAL 4>; /* SD_ANA_CON3 */
			6  = <0x0018 0 32 0x00004040 IDX_FIX_VAL 4>; /* SD_ANA_CON4 */
			7  = <0x0024 0 32 0x00000000 IDX_FIX_VAL 3>; /* SD_ANA_CON7 */
			8  = <0x0030 0  8 0x00000000 IDX_STL_VAL 4>; /* SD_TIME_CON0 */
			9  = <0x0030 8  1 0x00000000 IDX_STL_CLK 4>; /* SD_TIME_CON0 */
			10 = <0x0034 0 32 0x00000003 IDX_FIX_VAL 4>; /* SD_TIME_CON1 */
			11 = <0x0040 0  1 0x00000001 IDX_SKW_CAL 4>; /* SD_DESKEW_CON0 */
			12 = <0x0050 0 32 0x0000081A IDX_FIX_VAL 4>; /* SD_DESKEW_CON4 */
			/* Enable should be set at last. */
			13 = <0x0000 0 32 0x00000001 IDX_FIX_VAL 4>; /* SD_GNR_CON0 , Phy data enable */
		};
	};

	dcphy_setfile_cphy: dcphy-setfile-cphy@00 {
		comm {
			/* bias */
			0  = <0x1000 0 32 0x00000010 IDX_BIA_VAL 0>; /* M_BIAS_CON0 */
			1  = <0x1004 0 32 0x00000110 IDX_BIA_VAL 0>; /* M_BIAS_CON1 */
			2  = <0x1008 0 32 0x00003223 IDX_BIA_VAL 0>; /* M_BIAS_CON2 */
			3  = <0x1010 0 32 0x00000240 IDX_BIA_VAL 0>; /* M_BIAS_CON4 */
		};

		lane {
			0  = <0x0004 0 32 0x00003C00 IDX_FIX_VAL 3>; /* SD_GNR_CON1 */
			1  = <0x0008 0 32 0x000001F3 IDX_FIX_VAL 3>; /* SD_ANA_CON0 */
			2  = <0x000C 0 32 0x0000F6A9 IDX_FIX_VAL 3>; /* SD_ANA_CON1 */
			3  = <0x0010 0 32 0x00000005 IDX_FIX_VAL 3>; /* SD_ANA_CON2 */
			4  = <0x0014 0 32 0x00008600 IDX_FIX_VAL 3>; /* SD_ANA_CON3 */
			5  = <0x0018 0 32 0x00004040 IDX_FIX_VAL 3>; /* SD_ANA_CON4 */
			6  = <0x001c 0 32 0x00002200 IDX_FIX_VAL 3>; /* SD_ANA_CON5 */
			7  = <0x0020 0 32 0x00000E08 IDX_FIX_VAL 3>; /* SD_ANA_CON6 */
			8  = <0x0024 0 32 0x00000040 IDX_FIX_VAL 3>; /* SD_ANA_CON7 */
			9  = <0x0030 0  8 0x00000000 IDX_STL_VAL 3>; /* SD_TIME_CON0 */
			10 = <0x0030 8  1 0x00000000 IDX_STL_CLK 3>; /* SD_TIME_CON0 */
			11 = <0x0034 0 32 0x00000034 IDX_FIX_VAL 3>; /* SD_TIME_CON1 */
			12 = <0x0040 0  1 0x00000000 IDX_SKW_CAL 3>; /* SD_DESKEW_CON0 */
			13 = <0x005C 0 32 0x00001000 IDX_FIX_VAL 3>; /* SD_CRC_DLY_CON0 */
			14 = <0x0064 0 32 0x00001501 IDX_FIX_VAL 3>; /* SD_CRC_CON1 */
			15 = <0x0068 0 32 0x00000003 IDX_FIX_VAL 3>; /* SD_CRC_CON2 */
			16 = <0x009C 0 32 0x00000080 IDX_FIX_VAL 3>; /* SD_CRC_DLY_CON3 */
			/* Enable should be set at last. */
			17 = <0x0000 0 32 0x00000001 IDX_FIX_VAL 3>; /* SD_GNR_CON0 , Phy data enable */
		};
	};

	dphy_setfile: dphy-setfile@00 {
		comm {
			/* bias */
			0  = <0x1000 0 32 0x00000010 IDX_BIA_VAL 0>; /* M_BIAS_CON0 */
			1  = <0x1004 0 32 0x00000110 IDX_BIA_VAL 0>; /* M_BIAS_CON1 */
			2  = <0x1008 0 32 0x00003223 IDX_BIA_VAL 0>; /* M_BIAS_CON2 */
			3  = <0x1010 0 32 0x00000200 IDX_BIA_VAL 0>; /* M_BIAS_CON4 */

			/* Clock lane */
			4 = <0x0004 0 32 0x00003C00 IDX_FIX_VAL 0>; /* SC_GNR_CON1 */
			5 = <0x0008 0 32 0x00000001 IDX_FIX_VAL 0>; /* SC_ANA_CON0 */
			6 = <0x000C 0 32 0x0000F4AE IDX_FIX_VAL 0>; /* SC_ANA_CON1 */
			7 = <0x0010 0 32 0x00000002 IDX_FIX_VAL 0>; /* SC_ANA_CON2 */
			8 = <0x0014 0 32 0x00008600 IDX_FIX_VAL 0>; /* SC_ANA_CON3 */
			9 = <0x0018 0 32 0x00004000 IDX_FIX_VAL 0>; /* SC_ANA_CON4 */
			10 = <0x0030 0 32 0x00000409 IDX_FIX_VAL 0>; /* SC_TIME_CON0 */

			/* Enable should be set at last */
			11 = <0x0000 0 32 0x00000001 IDX_FIX_VAL 0>; /* SC_GNR_CON0 */
		};

		lane {
			0  = <0x0004 0 32 0x00003C00 IDX_FIX_VAL 4>; /* SD_GNR_CON1 */
			1  = <0x0008 0 32 0x00000001 IDX_FIX_VAL 4>; /* SD_ANA_CON0 */
			2  = <0x000C 0 32 0x0000F4AE IDX_FIX_VAL 4>; /* SD_ANA_CON1 */
			3  = <0x0010 0 32 0x00000002 IDX_FIX_VAL 4>; /* SD_ANA_CON2 */
			4  = <0x0010 8  2 0x00000000 IDX_SKW_DLY 4>; /* SD_ANA_CON2 */
			5  = <0x0014 0 32 0x00008600 IDX_FIX_VAL 4>; /* SD_ANA_CON3 */
			6  = <0x0018 0 32 0x00002000 IDX_FIX_VAL 4>; /* SD_ANA_CON4 */
			7  = <0x0030 0  8 0x00000000 IDX_STL_VAL 4>; /* SD_TIME_CON0 */
			8  = <0x0030 8  1 0x00000000 IDX_STL_CLK 4>; /* SD_TIME_CON0 */
			9  = <0x0034 0 32 0x00000003 IDX_FIX_VAL 4>; /* SD_TIME_CON1 */
			10 = <0x0040 0  1 0x00000001 IDX_SKW_CAL 4>; /* SD_DESKEW_CON0 */
			11 = <0x0050 0 32 0x0000081A IDX_FIX_VAL 4>; /* SD_DESKEW_CON4 */

			/* Enable should be set at last */
			12 = <0x0000 0 32 0x00000001 IDX_FIX_VAL 4>;/* SD_GNR_CON0 */
		};
	};

	dphy_setfile_2lane: dphy-setfile_2lane@00 {
		comm {
			/* bias */
			0  = <0x1000 0 32 0x00000010 IDX_BIA_VAL 0>; /* M_BIAS_CON0 */
			1  = <0x1004 0 32 0x00000110 IDX_BIA_VAL 0>; /* M_BIAS_CON1 */
			2  = <0x1008 0 32 0x00003223 IDX_BIA_VAL 0>; /* M_BIAS_CON2 */
			3  = <0x1010 0 32 0x00000200 IDX_BIA_VAL 0>; /* M_BIAS_CON4 */

			/* clock */
			4 = <0x0004 0 32 0x00003C00 IDX_FIX_VAL 0>; /* SC_GNR_CON1 */
			5 = <0x0008 0 32 0x00000001 IDX_FIX_VAL 0>; /* SC_ANA_CON0 */
			6 = <0x000C 0 32 0x0000EA40 IDX_FIX_VAL 0>; /* SC_ANA_CON1 */
			7 = <0x0010 0 32 0x00000002 IDX_FIX_VAL 0>; /* SC_ANA_CON2 */
			8 = <0x0014 0 32 0x00008600 IDX_FIX_VAL 0>; /* SC_ANA_CON3 */
			9 = <0x0018 0 32 0x00004000 IDX_FIX_VAL 0>; /* SC_ANA_CON4 */
			10 = <0x0030 0 32 0x00000000 IDX_FIX_VAL 0>; /* SC_TIME_CON0 */
			/* Enable should be set at last. */
			11 = <0x0000 0 32 0x00000001 IDX_FIX_VAL 0>; /* SC_GNR_CON0, Phy clock enable */
		};

		lane {
			0  = <0x0004 0 32 0x00003C00 IDX_FIX_VAL 2>; /* SD_GNR_CON1 */
			1  = <0x0008 0 32 0x00000001 IDX_FIX_VAL 2>; /* SD_ANA_CON0 */
			2  = <0x000C 0 32 0x0000F4AE IDX_FIX_VAL 2>; /* SD_ANA_CON1 */
			3  = <0x0010 0 32 0x00008082 IDX_FIX_VAL 2>; /* SD_ANA_CON2 */
			4  = <0x0010 8  2 0x00000000 IDX_SKW_DLY 2>; /* SD_ANA_CON2 */
			5  = <0x0014 0 32 0x00008600 IDX_FIX_VAL 2>; /* SD_ANA_CON3 */
			6  = <0x0018 0 32 0x00004000 IDX_FIX_VAL 2>; /* SD_ANA_CON4 */
			8  = <0x0030 0  8 0x00000000 IDX_STL_VAL 2>; /* SD_TIME_CON0 */
			9  = <0x0030 8  1 0x00000000 IDX_STL_CLK 2>; /* SD_TIME_CON0 */
			10 = <0x0034 0 32 0x00000003 IDX_FIX_VAL 2>; /* SD_TIME_CON1 */
			11 = <0x0040 0  1 0x00000001 IDX_SKW_CAL 2>; /* SD_DESKEW_CON0 */
			12 = <0x0050 0 32 0x0000081A IDX_FIX_VAL 2>; /* SD_DESKEW_CON4 */
			/* Enable should be set at last. */
			13 = <0x0000 0 32 0x00000001 IDX_FIX_VAL 2>; /* SD_GNR_CON0 , Phy data enable */
		};
	};
};
